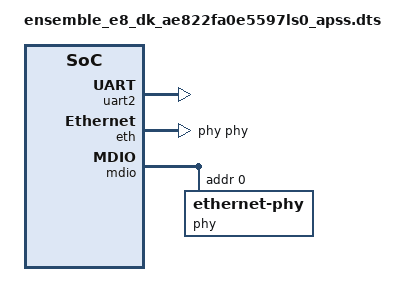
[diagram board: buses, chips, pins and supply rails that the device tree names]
/*
 * SPDX-FileCopyrightText: Copyright Alif Semiconductor
 * SPDX-License-Identifier: Apache-2.0
 */

/dts-v1/;

#include <alif/ensemble/ae822fa0e5597ls0.dtsi>
#include <alif/ensemble/ae822fa0e5597ls0_gic_irq.dtsi>
#include <alif/ensemble/common/ensemble_apss.dtsi>
#include "ensemble_e8_dk-pinctrl.dtsi"
#include "ensemble_e8_dk_common.dtsi"

/ {
	compatible = "alif,ensemble-e8-dk-ae822fa0e5597ls0-apss";

	chosen {
		zephyr,flash = &mram;
		zephyr,sram = &sram0;
		zephyr,console = &uart2;
		zephyr,shell-uart = &uart2;
	};
};

&uart2 {
	pinctrl-0 = <&uart2_default>;
	pinctrl-names = "default";
	status = "okay";
};

&eth {
	pinctrl-0 = <&eth_default>;
	pinctrl-names = "default";
	phy-handle = <&phy>;
	zephyr,random-mac-address;
	status = "okay";
};

&mdio {
	status = "okay";

	phy: ethernet-phy@0 {
		compatible = "ethernet-phy";
		reg = <0>;
		status = "okay";
	};
};

&ptp_clock {
	status = "okay";
};
